# CC2340R5 register map
File version: 1.0
CPU: CM0P 1.0, other endian, MPU, FPU, 3 interrupt priority bits
Registers are 32-bit, read-write, reset 0x0 unless marked. A register's access mark holds for its fields unless they carry their own. Offsets are from the block's base; [hi:lo] are bit positions; lines under a group give offsets from that group; {n}, {i} and the like mark numbered series.

## SPI0 — Serial Peripheral Interface (SPI) module with peripheral and controller capabilities.
Base 0x40030000
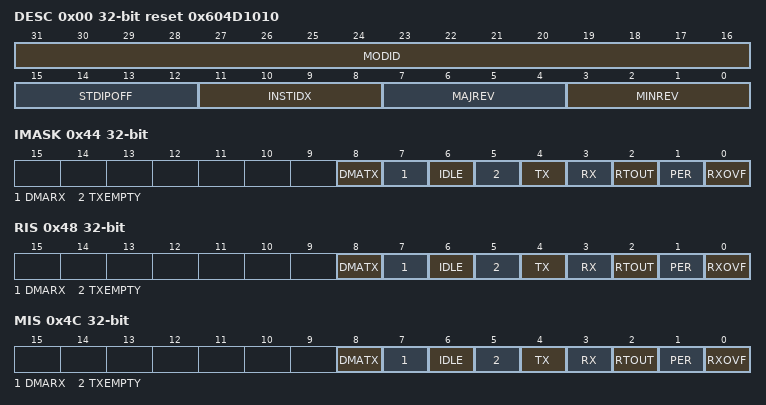
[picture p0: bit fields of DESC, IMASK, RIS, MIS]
0x00 DESC reset 0x604D1010 — Description Register. This register provides IP module ID, revision information, instance index and standard MMR registers offset.
  [31:16] MODID — [31:16] Module identifier used to uniquely identify this IP.
  [15:12] STDIPOFF — [15:12] Standard IP MMR block offset. Standard IP MMRs are the set of from aggregated IRQ registers till DTB. 0: Standard IP MMRs do not exist 0x1-0xF: Standard IP MMRs begin at offset of (64*STDIPOFF from the base IP address)
  [11:8] INSTIDX — [11:8] IP Instance ID number. If multiple instances of IP exist in the device, this field can identify the instance number (0-15).
  [7:4] MAJREV — [7:4] Major revision of IP (0-15).
  [3:0] MINREV — [3:0] Minor revision of IP (0-15).
0x44 IMASK — Interrupt mask. This register selects interrupt sources which are allowed to pass from RIS to MIS when the corresponding bit-fields are set to 1.
  [all] fields
    1=SET (Set Interrrupt Mask); 0=CLR (Clear Interrupt Mask)
  [8] DMATX — [8:8] DMA Done TX event mask.
  [7] DMARX — [7:7] DMA Done RX event mask.
  [6] IDLE — [6:6] SPI Idle event mask.
  [5] TXEMPTY — [5:5] Transmit FIFO Empty event mask.
  [4] TX — [4:4] Transmit FIFO event mask.
  [3] RX — [3:3] Receive FIFO event.
  [2] RTOUT — [2:2] SPI Receive Time-Out event mask.
  [1] PER — [1:1] Parity error event mask.
  [0] RXOVF — [0:0] RXFIFO overflow event mask.
0x48 RIS — Raw interrupt status. This register reflects the state of all pending interrupts, regardless of masking. This register allows the user to implement a poll scheme. A flag set in this register can be cleared by writing 1 to the corresponding ICLR register bit.
  [all] fields
    1=SET (Interrupt occurred); 0=CLR (Interrupt did not occur)
  [8] DMATX — [8:8] DMA Done event for TX. This interrupt is set if the TX DMA channel sends the DONE signal. This allows the handling of the TX DMA event inside SPI.
  [7] DMARX — [7:7] DMA Done event for RX. This interrupt is set if the RX DMA channel sends the DONE signal. This allows handling of the DMA RX event inside SPI.
  [6] IDLE — [6:6] SPI has completed transfers and moved to IDLE mode. This bit is set when STAT.BUSY goes low.
  [5] TXEMPTY — [5:5] Transmit FIFO Empty interrupt mask. This interrupt is set when all data in the Transmit FIFO has been moved to the shift register.
  [4] TX — [4:4] Transmit FIFO event.This interrupt is set if the selected Transmit FIFO level has been reached.
  [3] RX — [3:3] Receive FIFO event.This interrupt is set if the selected Receive FIFO level has been reached
  [2] RTOUT — [2:2] SPI Receive Time-Out event. This interrupt is set if no activity is detected on the input clock line within the time period dictated by CTL1.RTOUT value. This is applicable only in peripheral mode.
  [1] PER — [1:1] Parity error event. This bit is set if a Parity error has been detected
  [0] RXOVF — [0:0] RXFIFO overflow event. This interrupt is set if an RX FIFO overflow has been detected.
0x4C MIS — Masked interrupt status. This register is simply a bitwise AND of the contents of IMASK and RIS.*] registers. A flag set in this register can be cleared by writing 1 to the corresponding ICLR register bit.
  [all] fields
    1=SET (Interrupt occurred); 0=CLR (Interrupt did not occur)
  [8] DMATX — [8:8] Masked DMA Done event for TX.
  [7] DMARX — [7:7] Masked DMA Done event for RX.
  [6] IDLE — [6:6] Masked SPI IDLE event.
  [5] TXEMPTY — [5:5] Masked Transmit FIFO Empty event.
  [4] TX — [4:4] Masked Transmit FIFO event.
  [3] RX — [3:3] Masked receive FIFO event.
  [2] RTOUT — [2:2] Masked SPI Receive Time-Out event.
  [1] PER — [1:1] Masked Parity error event.
  [0] RXOVF — [0:0] Masked RXFIFO overflow event.
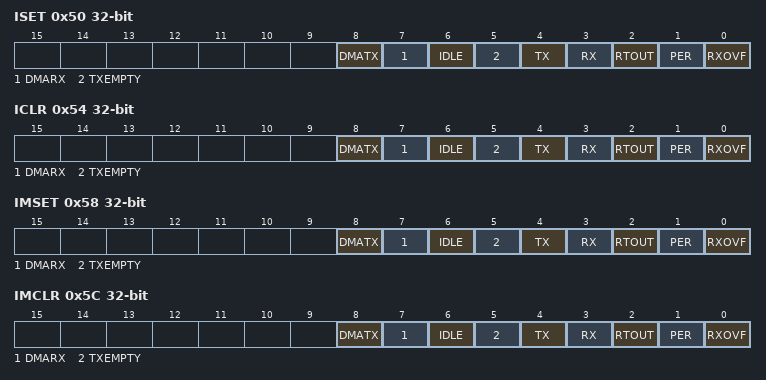
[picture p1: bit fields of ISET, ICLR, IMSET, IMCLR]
0x50 ISET — Interrupt set register. This register can used by software for diagnostics and safety checking purposes. Writing a 1 to a bit in this register will set the event and the corresponding RIS bit also gets set. If the corresponding IMASK bit is set, then the corresponding MIS register bit also gets set.
  [8] DMATX — [8:8] Set DMA Done event for TX.
    1=SET (Set Interrupt); 0=NOEFF (Writing 0 has no effect)
  [7] DMARX — [7:7] Set DMA Done event for RX.
    1=SET (Set Interrupt); 0=NOEFF (Writing 0 has no effect)
  [6] IDLE — [6:6] Set SPI IDLE event.
    1=SET (Set Interrupt); 0=NOEFF (Writing 0 has no effect)
  [5] TXEMPTY — [5:5] Set Transmit FIFO Empty event.
    1=SET (Set Interrupt); 0=NOEFF (Writing 0 has no effect)
  [4] TX — [4:4] Set Transmit FIFO event.
    1=SET (Set Interrupt); 0=NOEFF (Writing 0 has no effect)
  [3] RX — [3:3] Set Receive FIFO event.
    1=SET (Set Interrupt); 0=NOEFF (Writing 0 has no effect)
  [2] RTOUT — [2:2] Set SPI Receive Time-Out Event.
    1=SET (Set Interrrupt Mask); 0=NOEFF (Writing 0 has no effect)
  [1] PER — [1:1] Set Parity error event.
    1=SET (Set Interrupt); 0=NOEFF (Writing 0 has no effect)
  [0] RXOVF — [0:0] Set RXFIFO overflow event.
    1=SET (Set Interrupt); 0=NOEFF (Writing 0 has no effect)
0x54 ICLR — Interrupt clear register. This register allows software to clear interrupts. Writing a 1 to a bit in this register will clear the event and the corresponding RIS bit also gets cleared. If the corresponding IMASK bit is set, then the corresponding MIS register bit also gets cleared.
  [8] DMATX — [8:8] Clear DMA Done event for TX.
    1=CLR (Clear Interrupt); 0=NOEFF (Writing 0 has no effect)
  [7] DMARX — [7:7] Clear DMA Done event for RX.
    1=CLR (Clear Interrupt); 0=NOEFF (Writing 0 has no effect)
  [6] IDLE — [6:6] Clear SPI IDLE event.
    1=CLR (Clear Interrupt); 0=NOEFF (Writing 0 has no effect)
  [5] TXEMPTY — [5:5] Clear Transmit FIFO Empty event.
    1=CLR (Clear Interrupt); 0=NOEFF (Writing 0 has no effect)
  [4] TX — [4:4] Clear Transmit FIFO event.
    1=CLR (Clear Interrupt); 0=NOEFF (Writing 0 has no effect)
  [3] RX — [3:3] Clear Receive FIFO event.
    1=CLR (Clear Interrupt); 0=NOEFF (Writing 0 has no effect)
  [2] RTOUT — [2:2] Clear SPI Receive Time-Out Event.
    1=CLR (Set Interrrupt Mask); 0=NOEFF (Writing 0 has no effect)
  [1] PER — [1:1] Clear Parity error event.
    1=CLR (Clear Interrupt); 0=NOEFF (Writing 0 has no effect)
  [0] RXOVF — [0:0] Clear RXFIFO overflow event.
    1=CLR (Clear Interrupt); 0=NOEFF (Writing 0 has no effect)
0x58 IMSET — Interrupt mask set register. Writing a 1 to a bit in this register will set the corresponding IMASK bit.
  [all] fields
    1=SET (Set interrupt mask); 0=NOEFF (Writing 0 has no effect)
  [8] DMATX — [8:8] Set DMA Done for TX event mask
  [7] DMARX — [7:7] Set DMA Done for RX event mask
  [6] IDLE — [6:6] Set SPI IDLE event mask
  [5] TXEMPTY — [5:5] Set Transmit FIFO Empty event mask
  [4] TX — [4:4] Set Transmit FIFO event mask
  [3] RX — [3:3] Set Receive FIFO event mask
  [2] RTOUT — [2:2] Set SPI Receive Time-Out event mask
  [1] PER — [1:1] Set Parity error event mask
  [0] RXOVF — [0:0] Set RXFIFO overflow event mask
0x5C IMCLR — Interrupt mask clear register. Writing a 1 to a bit in this register will clear the corresponding IMASK bit.
  [all] fields
    1=CLR (Clear interrupt mask); 0=NOEFF (Writing 0 has no effect)
  [8] DMATX — [8:8] Clear DMA Done for TX event mask
  [7] DMARX — [7:7] Clear DMA Done for RX event mask
  [6] IDLE — [6:6] Clear SPI IDLE event mask
  [5] TXEMPTY — [5:5] Clear Transmit FIFO Empty event mask
  [4] TX — [4:4] Clear Transmit FIFO event mask
  [3] RX — [3:3] Clear Receive FIFO event mask
  [2] RTOUT — [2:2] Clear SPI Receive Time-Out event mask
  [1] PER — [1:1] Clear Parity error event mask
  [0] RXOVF — [0:0] Clear RXFIFO overflow event mask
0x60 EMU — Emulation control register. This register controls the behavior of the IP related to core halted input.
  [0] HALT — [0:0] Halt control
    1=STOP (Freeze option. The IP freezes functionality when the core halted input is asserted, and resumes when it is deasserted. The freeze can either be immediate or after the IP has reached a boundary (end of word boundary, based on DSS configuration) from where it can resume without corruption.); 0=RUN (Free run option. The IP ignores the state of the core halted input.)
0x64 DTB — Digital test bus control register. This register can be used to bring out IP internal signals to the pads for observation. 16 signals can be observed per select value.
  [2:0] SEL — [2:0] Digital test bus selection mux control. Non-zero select values output a 16 bit selected group of signals per value.
    0=DIS (All 16 observation signal outputs are set to zero.)
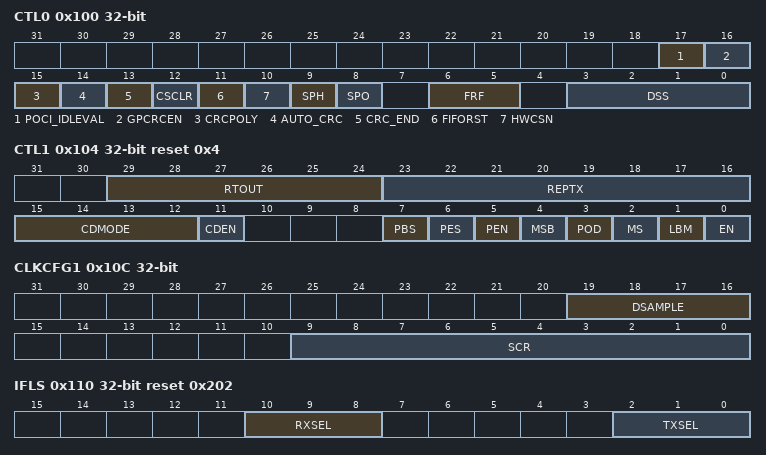
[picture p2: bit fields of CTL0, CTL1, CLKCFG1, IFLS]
0x100 CTL0 — SPI control register 0
  [17] POCI_IDLEVAL — [17:17] The Idle value of POCI - when TXFIFO is empty and before data is writtern into TXFIFO - can be controlled by this field.
    1=IDLE_ONE (POCI outputs idle value of '1'); 0=IDLE_ZERO (POCI output idle value of '0')
  [16] GPCRCEN — [16:16] General purpose CRC enable. This bit enables transmit side CRC unit for general purpose use by software when SPI is disabled (CTL1.EN = 0). This bit must be 0 when SPI is enabled.
    1=ENA (Transmit side CRC unit is available for general purpose software use); 0=DIS (Transmit side CRC unit is not available for general purpose software use)
  [15] CRCPOLY — [15:15] CRC polynomial selection.
    1=BIT16 (Selects 16-bit CCITT CRC polynomial); 0=BIT8 (Selects 8-bit CCITT CRC polynomial)
  [14] AUTO_CRC — [14:14] Auto insert CRC
    1=ENA (Insert CRC into TXFIFO upon TXFIFO underflow); 0=DIS (Do not insert CRC into TXFIFO upon TXFIFO underflow)
  [13] CRC_END — [13:13] CRC16 Endianness
    1=CRC_END_LSB (Auto-insertion of CRC16 is least-significant byte first); 0=CRC_END_MSB (Auto-insertion of CRC16 is most-significant byte first)
  [12] CSCLR — [12:12] Clear shift register counter on CS inactive. This bit is relevant only in the peripheral mode, when CTL1.MS=0.
    1=ENA (Enable automatic clear of shift register when CS goes inactive.); 0=DIS (Disable automatic clear of shift register when CS goes inactive.)
  [11] FIFORST — [11:11] This bit is used to reset transmit and receive FIFO pointers. This bit is auto cleared once the FIFO pointer reset operation is completed.
    1=RST_TRIG (Trigger FIFO pointers reset when written to 1.); 0=RST_DONE (FIFO pointers reset completed when 0 is read)
  [10] HWCSN — [10:10] Hardware controlled chip select (CS) value. When set CS is zero till TX FIFO is empty, as in - a. CS is de-asserted b. All data bytes are transmitted c. CS is asserted
    1=ENA (HWCS Enable); 0=DIS (HWCS Disable)
  [9] SPH — [9:9] CLKOUT phase (Motorola SPI frame format only). This bit selects the clock edge that captures data and enables it to change state. It has the most impact on the first bit transmitted by either permitting or not permitting a clock transition before the first data capture clock edge.
    1=SECOND (Data is captured on the second clock edge transition.); 0=FIRST (Data is captured on the first clock edge transition.)
  [8] SPO — [8:8] CLKOUT polarity (Motorola SPI frame format only).
    1=HIGH (SPI produces a steady state HIGH value on the CLKOUT); 0=LOW (SPI produces a steady state LOW value on the CLKOUT)
  [6:5] FRF — [6:5] Frame format select
    3=MIRCOWIRE (National Microwire frame format); 2=TI_SYNC (TI synchronous serial frame format); 1=MOTOROLA_4WIRE (Motorola SPI frame format (4 wire mode)); 0=MOTOROLA_3WIRE (Motorola SPI frame format (3 wire mode))
  [3:0] DSS — [3:0] Data size select. Valid DSS values for controller mode operation are 0x3 to 0xF and for peripheral mode operation are 0x6 to 0xF. DSS values 0x0 to 0x2 are reserved and shall not be used.
    {v}=BITS_{v+1} ({v+1}-bits data size) (v=3..15)
0x104 CTL1 reset 0x4 — SPI control register 1
  [29:24] RTOUT — [29:24] Receive Timeout (only for Peripheral mode) Defines the number of Clock Cycles before after which the Receive Timeout flag RIS.RTOUT is set. The time is calculated using the control register for the clock selection and divider in the Controller mode configuration. A value of 0 disables this function.
  [23:16] REPTX — [23:16] Counter to repeat last transfer 0: repeat last transfer is disabled. x: repeat the last transfer with the provided value. The transfer will be started with writing a data into the TX FIFO. Sending the data will be repeated provided value number of times, so the data will be transferred x+1 times in total. The behavior would be as if the data were be written into the TX FIFO as many times as defined by the value here additionally. It can be used to clean a transfer or to pull a certain amount of data by a peripheral.
    0=DIS (REPTX disable)
  [15:12] CDMODE — [15:12] Commnd Data Model. This bit field value determines the behavior of C/D or CS signal when CDEN = 1. CS pin held low indicates command phase and CS pin held high indicates data phase. When CDMODE = 0x0, the CS pin is always held high during transfer indicating data phase only operation (manual mode). When CDMODE = 0xF, the CS pin is always held low during transfer indicating command phase only operation (manual mode). When CDMODE = 0x1 to 0xE, the CS pin is held low for the number of bytes indicated by CDMODE value for the command phase and held high for the remaining transfers in the data phase (automatic mode). When CDMODE is set to value 0x1 to 0xE, reading CDMODE at any time during operation indicates the remaining bytes to be transferred in the command phase.
    15=COMMAND (Manual mode: Command); 0=DATA (Manual mode: Data)
  [11] CDEN — [11:11] Command/Data mode enable. This feature is applicable only in controller mode and for 8-bit transfers (CTL0.DSS = 7). The chip select pin is used for command/data signaling in Motorola SPI frame format (3-wire) operation.
    1=ENA (C/D Mode Enable); 0=DIS (C/D Mode Disable)
  [7] PBS — [7:7] Parity bit select
    1=BIT1 (Bit 1 is used for Parity, Bit 0 is ignored); 0=BIT0 (Bit 0 is used for Parity)
  [6] PES — [6:6] Even parity select.
    1=EVEN (Even Parity mode); 0=ODD (Odd Parity mode)
  [5] PEN — [5:5] Parity enable. If enabled the last bit will be used as parity to evaluate the correct reception of the previous bits. In case of parity mismatch the parity error flag RIS.PER will be set. This feature is available only in SPI controller mode.
    1=ENA (Enable Parity function); 0=DIS (Disable Parity function)
  [4] MSB — [4:4] MSB first select. Controls the direction of receive and transmit shift register. MSB first configuration (MSB = 1) must be selected when CRC feature is used for SPI communication.
    1=MSB (MSB first); 0=LSB (LSB first)
  [3] POD — [3:3] Peripheral data output disable. This bit is relevant only in the peripheral mode, MS=1. In multiple-peripheral systems, it is possible for a SPI controller to broadcast a message to all peripherals in the system while ensuring that only one peripheral drives data onto its serial output line. In such systems the POCI lines from multiple peripherals could be tied together. To operate in such systems, this bit field can be set if the SPI peripheral is not supposed to drive the POCI output.
    1=ENA (SPI cannot drive the POCI output in peripheral mode.); 0=DIS (SPI can drive the POCI output in peripheral mode.)
  [2] MS — [2:2] Controller or peripheral mode select. This bit can be modified only when SPI is disabled, CTL1.EN=0.
    1=CONTROLLER (Select Controller mode); 0=PERIPHERAL (Select Peripheral mode)
  [1] LBM — [1:1] Loop back mode control
    1=ENA (Enable loopback mode. Output of transmit serial shifter is connected to input of receive serial shifter internally.); 0=DIS (Disable loopback mode. Normal serial port operation enabled.)
  [0] EN — [0:0] SPI enable.
    1=ENA (SPI Enabled and released for operation.); 0=DIS (SPI is disabled)
0x108 CLKCFG0 — Clock configuration register 0. This register is used to configure the clock prescaler.
  [2:0] PRESC — [2:0] Prescaler configuration
    {v}=DIV_BY_{v+1} (Divide clock source by {v+1}) (v=1..7); 0=DIV_BY_1 (Do not divide clock source)
0x10C CLKCFG1 — Clock configuration register 1. This register is used to configure serial clock rate and clock count for delayed sampling in controller mode.
  [19:16] DSAMPLE — [19:16] Delayed sampling. In controller mode the data on the input pin will be delayed sampled by the defined clock cycles. DSAMPLE values can range from 0 to SCR+1. Typically, values of 1 or 2 would suffice.
  [9:0] SCR — [9:0] Serial clock divider. This is used to generate the transmit and receive bit rate of the SPI. The SPI bit rate: (SPI's functional clock frequency)/((SCR+1)*2). SCR value can be from 0 to1023.
0x110 IFLS reset 0x202 — Interrupt FIFO level select register. This register can be used to define the levels at which the RIS.TX, RIS.RX flags are triggered. The interrupts are generated based on FIFO level. Out of reset, the IFLS.TXSEL and IFLS.RXSEL bits are configured so that the FIFOs trigger an interrupt at the half-way mark.
  [10:8] RXSEL — [10:8] Receive FIFO Level Select. The trigger points for the receive interrupt are as follows:
    7=LEVEL_1 (Trigger when RX FIFO contains $gt;= 1 byte); 6=LVL_RES6 (Reserved); 5=LVL_FULL (RX FIFO is full); 4=LVL_RES4 (Reserved); 3=LVL_3_4 (RX FIFO $gt;= 3/4 full); 2=LVL_1_2 (RX FIFO $gt;= 1/2 full (default)); 1=LVL_1_4 (RX FIFO $gt;= 1/4 full); 0=LVL_OFF (Reserved)
  [2:0] TXSEL — [2:0] Transmit FIFO Level Select. The trigger points for the transmit interrupt are as follows:
    7=LEVEL_1 (Trigger when TX FIFO has $gt;= 1 byte free); 6=LVL_RES6 (Reserved); 5=LVL_EMPTY (TX FIFO is empty); 4=LVL_RES4 (Reserved); 3=LVL_1_4 (TX FIFO $lt;= 1/4 empty); 2=LVL_1_2 (TX FIFO $lt;= 1/2 empty (default)); 1=LVL_3_4 (TX FIFO $lt;= 3/4 empty); 0=LVL_OFF (Reserved)
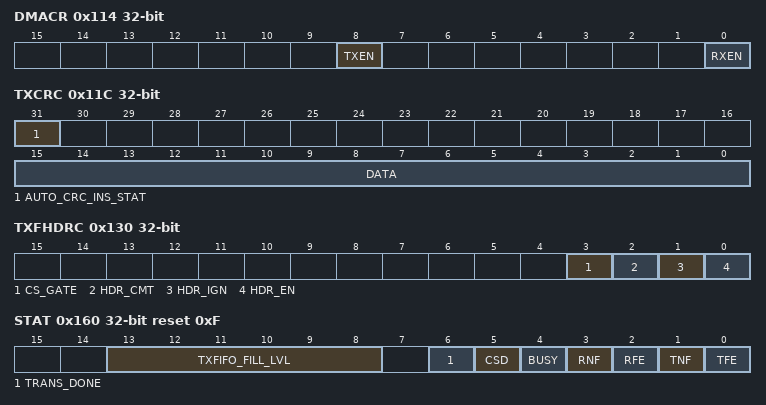
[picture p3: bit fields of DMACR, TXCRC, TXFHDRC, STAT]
0x114 DMACR — DMA Control Register
  [8] TXEN — [8:8] Transmit DMA enable. If this bit is set to 1, DMA for the trasmit FIFO is enabled.
    1=ENA (Enable TX DMA); 0=DIS (Disable TX DMA)
  [0] RXEN — [0:0] Receive DMA enable. If this bit is set to 1, DMA for the receive FIFO is enabled.
    1=ENA (Enable RX DMA); 0=DIS (Disable RX DMA)
0x118 RXCRC — Receive CRC register. Reading this register provides the computed CRC value from the receive side CRC unit. Reading this register or writing to this register with any value auto initializes the seed. The seed value is 0xFF when CTL0.CRCPOLY = 0 and 0xFFFF when CTL0.CRCPOLY = 1 for CCITT CRC polynomials. Bits[15:8] are a don't care when CTL0.CRCPOLY = 0.
  [15:0] DATA — [15:0] CRC value
0x11C TXCRC — Transmit CRC register. Reading this register provides the computed CRC value from the transmit side CRC unit. Reading this register or writing to this register with any value auto initializes the seed. The seed value is 0xFF when CTL0.CRCPOLY = 0 and 0xFFFF when CTL0.CRCPOLY = 1 for CCITT CRC polynomials. Bits[15:8] are a don't care when CTL0.CRCPOLY = 0.
  [31] AUTO_CRC_INS_STAT ro — [31:31] Status to indicate if Auto CRC has been inserted into TXFIFO. This is valid only if CTL0.AUTO_CRC enable bit is set
    1=INS (Auto CRC inserted); 0=NOTINS (Auto CRC not yet inserted)
  [15:0] DATA — [15:0] CRC value
0x120 TXFHDR32 — Header update reigster for 32 bits of header data.
  [31:0] DATA wo — [31:0] This field can be used to write four bytes of header data
0x124 TXFHDR24 — Header update reigster for 24 bits of header data.
  [31:0] DATA wo — [31:0] This field can be used to write three bytes of header data
0x128 TXFHDR16 — Header update reigster for 16 bits of data.
  [31:0] DATA wo — [31:0] This field can be used to write two bytes of header data
0x12C TXFHDR8 — Header update reigster for 8 bits of header data.
  [31:0] DATA wo — [31:0] This field can be used to write one byte of header data
    1=MAXIMUM (Highest possible value); 0=MINIMUM (Smallest possible value)
0x130 TXFHDRC — Atomic Header Control register
  [3] CS_GATE — [3:3] Chip Select Gating control register. If this bit is set header update register writes are blocked when chip select (CS) is active low, and HDR_IGN bit is set This bit resets to 0.
    1=BLK (Header update register writes are blocked when CS is active (low)); 0=UNBLK (Header update register writes are not blocked based on CS status)
  [2] HDR_CMT — [2:2] Header Committed field. This bit is set when the HDR_EN bit is set and CS is sampled low. This bit remains 0 otherwise. When set, this bit can be written to a value of 0 to clear.
    1=SET (Header update is committed); 0=CLR (Header update is not committed)
  [1] HDR_IGN — [1:1] Header Ignored field. When CS_GATE is set to BLK, this bit is set when the last Header update register(MMR_TXFHDRn.*) is written when CS is low or HDR_CMT is already set. When CS_GATE is set to UNBLK, this bit is set only when the header update register is written when HDR_CMT is already set. This bit remains 0 otherwise. When set, this bit can be written to a value of 0 to clear.
    1=CLR (Header update is not ignored)
  [0] HDR_EN — [0:0] Header enable field. When CS_GATE is set to BLK, this bit has to be set by software to enable this feature. When CS_GATE is set to UNBLK, this field is set automatically whenever a write to header update registers occurs MMR_TXFHDRn
    1=ENA (Atomic header udpate feature enable); 0=DIS (Atomic header update feature disable)
0x140 RXDATA — RXDATA Register. Reading this register returns first value in the RX FIFO. If the FIFO is empty the last read value is returned. Writing has no effect and is ignored.
  [15:0] DATA ro — [15:0] Received Data. When read, the entry in the receive FIFO, pointed to by the current FIFO read pointer is accessed. As data values are read by the receive logic from the incoming data frame, they are placed into the entry in the receive FIFO, pointed to by the current RX FIFO write pointer. Received data less than 16 bits is automatically right-justified in the receive buffer.
0x150 TXDATA — TXDATA Register. Writing a value in this register puts the data into the TX FIFO. Reading this register returns the last writen value.
  [15:0] DATA — [15:0] Transmit Data. When read, the last entry in the transmit FIFO, pointed to by the current FIFO write pointer is accessed. When written, the entry in the TX FIFO pointed to by the write pointer, is written to. Data values are read from the transmit FIFO by the transmit logic. It is loaded into the transmit serial shifter, then serially shifted out onto the output pin at the programmed bit rate. When a data size of less than 16 bits is selected, the user must right-justify data written to the transmit FIFO. The transmit logic ignores the unused bits.
0x160 STAT reset 0xF — Status Register
  [13:8] TXFIFO_FILL_LVL ro — [13:8] Indicates how many locations of TXFIFO is currently filled with data
  [6] TRANS_DONE — [6:6] Transmit done. Indicates whether the last bit left the Shift register after a transmission
    1=TRANSMIT_DONE (Last bit has been shifted out, and the transmission is done); 0=TRANSMIT_ONGOING (Last bit has not yet left the Shift register, and the transmission is ongoing.)
  [5] CSD — [5:5] Detection of CS deassertion in the middle of a word transmission results in this error being set. This feature is only available in the peripheral mode.
    1=ERR (An error is generated when CS posedge (deassertion) is detected before the entire word is transmitted.); 0=NOERR (No CS posedge is detected before the entire word has been transmitted.)
  [4] BUSY ro — [4:4] SPI Busy status
    1=ACTIVE (SPI is currently transmitting and/or recieving data, or transmit FIFO is not empty.); 0=IDLE (SPI is in idle mode.)
  [3] RNF ro — [3:3] Receive FIFO not full status.
    1=NOT_FULL (Receive FIFO is not full.); 0=FULL (Receive FIFO is full.)
  [2] RFE ro — [2:2] Receive FIFO empty status.
    1=EMPTY (Receive FIFO is empty.); 0=NOT_EMPTY (Receive FIFO is not empty.)
  [1] TNF ro — [1:1] Transmit FIFO not full status.
    1=NOT_FULL (Transmit FIFO is not full.); 0=FULL (Transmit FIFO is full.)
  [0] TFE ro — [0:0] Transmit FIFO empty status.
    1=EMPTY (Transmit FIFO is empty.); 0=NOT_EMPTY (Transmit FIFO is not empty.)
